# VPAC0_COMMON_0_IVPAC_TOP_0_CFG_SLV_PAR_VPAC_VISS0_S_VBUSP_VISS_RAWFE_CFG_MMR_S_VBUSP_RAWFE_CFG register map
Vendor: Texas Instruments
Peripheral module from a debugger description file (folder am62A).
Registers are 32-bit, read-write, reset 0x0 unless marked. A register's access mark holds for its fields unless they carry their own. Offsets are as the file gives them; lines under a group give offsets from that group; [hi:lo] are bit positions; {n}, {i} and the like mark numbered series; 'fields as' and 'values as' point back to an identical list; <NAME> marks a mode.

## VPAC0_COMMON_0_IVPAC_TOP_0_CFG_SLV_PAR_VPAC_VISS0_S_VBUSP_VISS_RAWFE_CFG_MMR_S_VBUSP_RAWFE_CFG
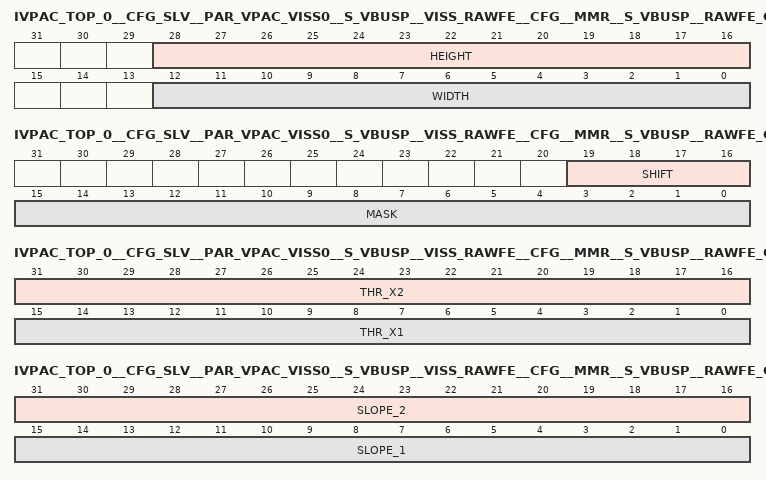
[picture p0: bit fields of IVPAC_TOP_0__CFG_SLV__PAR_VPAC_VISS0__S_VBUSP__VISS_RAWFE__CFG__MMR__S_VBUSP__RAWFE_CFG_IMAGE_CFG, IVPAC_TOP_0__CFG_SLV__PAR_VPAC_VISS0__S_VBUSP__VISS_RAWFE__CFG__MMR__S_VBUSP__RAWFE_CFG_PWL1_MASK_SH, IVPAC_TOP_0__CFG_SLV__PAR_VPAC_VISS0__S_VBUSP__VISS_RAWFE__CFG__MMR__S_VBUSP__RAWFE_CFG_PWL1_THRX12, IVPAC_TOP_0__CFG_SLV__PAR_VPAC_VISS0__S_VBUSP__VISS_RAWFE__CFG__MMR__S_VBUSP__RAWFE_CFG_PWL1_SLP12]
0x00 IVPAC_TOP_0__CFG_SLV__PAR_VPAC_VISS0__S_VBUSP__VISS_RAWFE__CFG__MMR__S_VBUSP__RAWFE_CFG_IMAGE_CFG — Input image width and height.
  [28:16] HEIGHT — image height
  [12:0] WIDTH — image width
0x04 IVPAC_TOP_0__CFG_SLV__PAR_VPAC_VISS0__S_VBUSP__VISS_RAWFE__CFG__MMR__S_VBUSP__RAWFE_CFG_SHADOW_CFG — shadow configuration
  [0] LUT3_SHDW_EN — use LUT2 ram as LUT table for LUT3 processing
0x08 IVPAC_TOP_0__CFG_SLV__PAR_VPAC_VISS0__S_VBUSP__VISS_RAWFE__CFG__MMR__S_VBUSP__RAWFE_CFG_PWL1_MASK_SH — Long frame PWL mask and shift values
  [19:16] SHIFT — number of right shift
  [15:0] MASK — mask bit pattern
0x0C IVPAC_TOP_0__CFG_SLV__PAR_VPAC_VISS0__S_VBUSP__VISS_RAWFE__CFG__MMR__S_VBUSP__RAWFE_CFG_PWL1_EN — Long frame PWL enable
  [0] ENABLE
0x10 IVPAC_TOP_0__CFG_SLV__PAR_VPAC_VISS0__S_VBUSP__VISS_RAWFE__CFG__MMR__S_VBUSP__RAWFE_CFG_PWL1_THRX12 — Long frame PWL threshold X1 and X2 - Unsigned
  [31:16] THR_X2 — threshold X2
  [15:0] THR_X1 — threshold X1
0x14 IVPAC_TOP_0__CFG_SLV__PAR_VPAC_VISS0__S_VBUSP__VISS_RAWFE__CFG__MMR__S_VBUSP__RAWFE_CFG_PWL1_THRX3 — Long frame PWL threshold X3 - Unsigned
  [15:0] THR_X3 — threshold X3
{0x14+4i} IVPAC_TOP_0__CFG_SLV__PAR_VPAC_VISS0__S_VBUSP__VISS_RAWFE__CFG__MMR__S_VBUSP__RAWFE_CFG_PWL1_THRY{i} (i=1..3) — Long frame PWL threshold Y{i} - Unsigned
  [23:0] THR_Y{i} — threshold Y{i}
0x24 IVPAC_TOP_0__CFG_SLV__PAR_VPAC_VISS0__S_VBUSP__VISS_RAWFE__CFG__MMR__S_VBUSP__RAWFE_CFG_PWL1_SLP12 — Long frame PWL slope 1 and 2 - Unsigned
  [31:16] SLOPE_2, [15:0] SLOPE_1
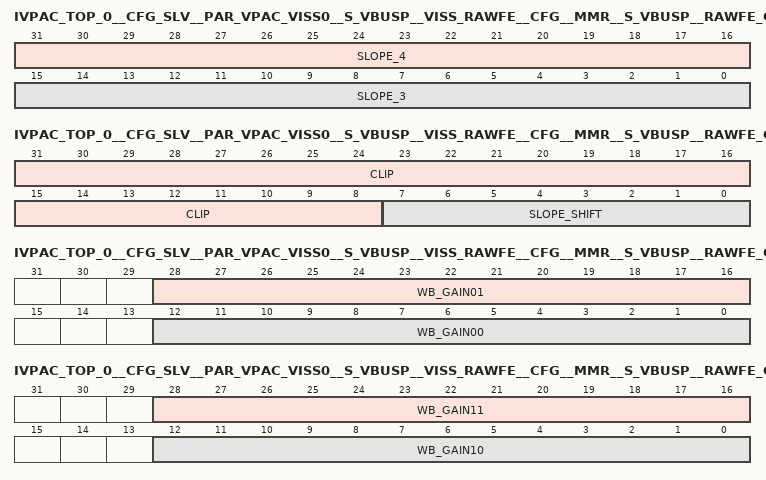
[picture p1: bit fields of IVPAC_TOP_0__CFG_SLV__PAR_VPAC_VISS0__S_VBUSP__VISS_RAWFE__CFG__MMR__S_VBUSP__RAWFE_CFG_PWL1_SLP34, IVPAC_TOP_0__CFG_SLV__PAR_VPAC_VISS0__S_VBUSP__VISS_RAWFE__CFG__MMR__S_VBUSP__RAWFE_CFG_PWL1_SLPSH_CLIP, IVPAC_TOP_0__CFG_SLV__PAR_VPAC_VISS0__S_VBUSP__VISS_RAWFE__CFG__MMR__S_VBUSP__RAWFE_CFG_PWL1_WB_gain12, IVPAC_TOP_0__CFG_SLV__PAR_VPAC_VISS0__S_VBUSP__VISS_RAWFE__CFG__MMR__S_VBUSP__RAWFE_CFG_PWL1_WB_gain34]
0x28 IVPAC_TOP_0__CFG_SLV__PAR_VPAC_VISS0__S_VBUSP__VISS_RAWFE__CFG__MMR__S_VBUSP__RAWFE_CFG_PWL1_SLP34 — Long frame PWL slope 3 and 4 - Unsigned
  [31:16] SLOPE_4, [15:0] SLOPE_3
0x2C IVPAC_TOP_0__CFG_SLV__PAR_VPAC_VISS0__S_VBUSP__VISS_RAWFE__CFG__MMR__S_VBUSP__RAWFE_CFG_PWL1_SLPSH_CLIP — Long frame PWL slope shift and clip
  [31:8] CLIP — clip value
  [7:0] SLOPE_SHIFT — shift value for slope, must not exceed decimal 31.
0x30 IVPAC_TOP_0__CFG_SLV__PAR_VPAC_VISS0__S_VBUSP__VISS_RAWFE__CFG__MMR__S_VBUSP__RAWFE_CFG_PWL1_OFF1 access not given — Long frame Offset 1
  [23:0] OFST00 rw — S24, Offset at pixel 00
0x34 IVPAC_TOP_0__CFG_SLV__PAR_VPAC_VISS0__S_VBUSP__VISS_RAWFE__CFG__MMR__S_VBUSP__RAWFE_CFG_PWL1_OFF2 access not given — Long frame Offset 2
  [23:0] OFST01 rw — S24, Offset at pixel 01
0x38 IVPAC_TOP_0__CFG_SLV__PAR_VPAC_VISS0__S_VBUSP__VISS_RAWFE__CFG__MMR__S_VBUSP__RAWFE_CFG_PWL1_OFF3 access not given — Long frame Offset 3
  [23:0] OFST10 rw — S24, Offset at pixel 10
0x3C IVPAC_TOP_0__CFG_SLV__PAR_VPAC_VISS0__S_VBUSP__VISS_RAWFE__CFG__MMR__S_VBUSP__RAWFE_CFG_PWL1_OFF4 access not given — Long frame Offset 4
  [23:0] OFST11 rw — S24, Offset at pixel 11
0x40 IVPAC_TOP_0__CFG_SLV__PAR_VPAC_VISS0__S_VBUSP__VISS_RAWFE__CFG__MMR__S_VBUSP__RAWFE_CFG_PWL1_WB_gain12 — Long Frame white balance gain 1 and 2
  [28:16] WB_GAIN01 — U13Q9, WB gain at pixel 01
  [12:0] WB_GAIN00 — U13Q9, WB gain at pixel 00
0x44 IVPAC_TOP_0__CFG_SLV__PAR_VPAC_VISS0__S_VBUSP__VISS_RAWFE__CFG__MMR__S_VBUSP__RAWFE_CFG_PWL1_WB_gain34 — Long Frame white balance gain 3 and 4
  [28:16] WB_GAIN11 — U13Q9, WB gain at pixel 11
  [12:0] WB_GAIN10 — U13Q9, WB gain at pixel 10
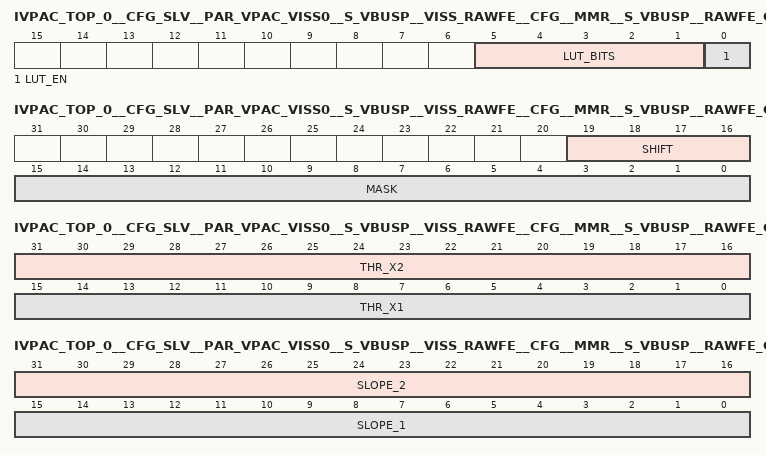
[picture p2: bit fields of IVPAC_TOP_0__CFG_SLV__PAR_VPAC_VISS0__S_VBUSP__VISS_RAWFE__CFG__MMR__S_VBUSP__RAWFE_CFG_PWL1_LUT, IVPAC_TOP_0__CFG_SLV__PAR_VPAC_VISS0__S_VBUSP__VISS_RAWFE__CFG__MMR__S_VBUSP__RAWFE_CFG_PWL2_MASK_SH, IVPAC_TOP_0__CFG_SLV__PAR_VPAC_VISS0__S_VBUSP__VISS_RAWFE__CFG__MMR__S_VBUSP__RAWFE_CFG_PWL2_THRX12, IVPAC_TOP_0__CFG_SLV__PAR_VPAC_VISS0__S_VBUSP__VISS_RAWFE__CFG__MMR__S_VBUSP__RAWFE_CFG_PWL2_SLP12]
0x48 IVPAC_TOP_0__CFG_SLV__PAR_VPAC_VISS0__S_VBUSP__VISS_RAWFE__CFG__MMR__S_VBUSP__RAWFE_CFG_PWL1_LUT — Long frame PWL LUT configuration
  [5:1] LUT_BITS — LUT input bit depth, up to 24
  [0] LUT_EN — enable LUT based compression
0x4C IVPAC_TOP_0__CFG_SLV__PAR_VPAC_VISS0__S_VBUSP__VISS_RAWFE__CFG__MMR__S_VBUSP__RAWFE_CFG_PWL1_LUTCLIP — Long frame PWL LUT output clip value
  [15:0] LUTCLIP — LUT clip value
0x50 IVPAC_TOP_0__CFG_SLV__PAR_VPAC_VISS0__S_VBUSP__VISS_RAWFE__CFG__MMR__S_VBUSP__RAWFE_CFG_PWL2_MASK_SH — Short frame PWL mask and shift values
  fields as IVPAC_TOP_0__CFG_SLV__PAR_VPAC_VISS0__S_VBUSP__VISS_RAWFE__CFG__MMR__S_VBUSP__RAWFE_CFG_PWL1_MASK_SH
0x54 IVPAC_TOP_0__CFG_SLV__PAR_VPAC_VISS0__S_VBUSP__VISS_RAWFE__CFG__MMR__S_VBUSP__RAWFE_CFG_PWL2_EN — Short frame PWL enable
  [0] ENABLE
0x58 IVPAC_TOP_0__CFG_SLV__PAR_VPAC_VISS0__S_VBUSP__VISS_RAWFE__CFG__MMR__S_VBUSP__RAWFE_CFG_PWL2_THRX12 — Short frame PWL threshold X1 and X2 - Unsigned
  [31:16] THR_X2 — threshold X2
  [15:0] THR_X1 — threshold X1
0x5C IVPAC_TOP_0__CFG_SLV__PAR_VPAC_VISS0__S_VBUSP__VISS_RAWFE__CFG__MMR__S_VBUSP__RAWFE_CFG_PWL2_THRX3 — Short frame PWL threshold X3 - Unsigned
  [15:0] THR_X3 — threshold X3
{0x5C+4i} IVPAC_TOP_0__CFG_SLV__PAR_VPAC_VISS0__S_VBUSP__VISS_RAWFE__CFG__MMR__S_VBUSP__RAWFE_CFG_PWL2_THRY{i} (i=1..3) — Short frame PWL threshold Y{i} - Unsigned
  [23:0] THR_Y{i} — threshold Y{i}
0x6C IVPAC_TOP_0__CFG_SLV__PAR_VPAC_VISS0__S_VBUSP__VISS_RAWFE__CFG__MMR__S_VBUSP__RAWFE_CFG_PWL2_SLP12 — Short frame PWL slope 1 and 2 - Unsigned
  [31:16] SLOPE_2, [15:0] SLOPE_1
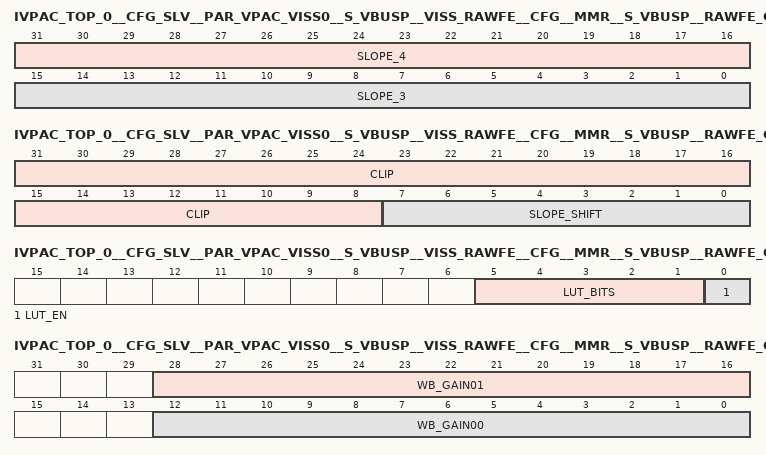
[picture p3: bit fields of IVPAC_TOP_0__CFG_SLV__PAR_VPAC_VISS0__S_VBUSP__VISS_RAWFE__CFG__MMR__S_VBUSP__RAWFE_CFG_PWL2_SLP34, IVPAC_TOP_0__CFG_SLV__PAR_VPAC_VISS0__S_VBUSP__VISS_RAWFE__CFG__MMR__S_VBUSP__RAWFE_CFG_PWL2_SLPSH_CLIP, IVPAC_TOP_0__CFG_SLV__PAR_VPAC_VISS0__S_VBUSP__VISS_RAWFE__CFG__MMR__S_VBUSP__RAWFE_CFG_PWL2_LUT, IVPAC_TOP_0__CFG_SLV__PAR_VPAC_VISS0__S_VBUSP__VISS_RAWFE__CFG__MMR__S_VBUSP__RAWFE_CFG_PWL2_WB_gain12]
0x70 IVPAC_TOP_0__CFG_SLV__PAR_VPAC_VISS0__S_VBUSP__VISS_RAWFE__CFG__MMR__S_VBUSP__RAWFE_CFG_PWL2_SLP34 — Short frame PWL slope 3 and 4 - Unsigned
  [31:16] SLOPE_4, [15:0] SLOPE_3
0x74 IVPAC_TOP_0__CFG_SLV__PAR_VPAC_VISS0__S_VBUSP__VISS_RAWFE__CFG__MMR__S_VBUSP__RAWFE_CFG_PWL2_SLPSH_CLIP — Short frame PWL slope shift and clip
  [31:8] CLIP — clip value
  [7:0] SLOPE_SHIFT — shift value for slope, must not exceed decimal 31
0x78 IVPAC_TOP_0__CFG_SLV__PAR_VPAC_VISS0__S_VBUSP__VISS_RAWFE__CFG__MMR__S_VBUSP__RAWFE_CFG_PWL2_LUT — Short frame PWL LUT configuration
  fields as IVPAC_TOP_0__CFG_SLV__PAR_VPAC_VISS0__S_VBUSP__VISS_RAWFE__CFG__MMR__S_VBUSP__RAWFE_CFG_PWL1_LUT
0x7C IVPAC_TOP_0__CFG_SLV__PAR_VPAC_VISS0__S_VBUSP__VISS_RAWFE__CFG__MMR__S_VBUSP__RAWFE_CFG_PWL2_LUTCLIP — Short frame PWL LUT output clip value
  [15:0] LUTCLIP — LUT clip value
0x80 IVPAC_TOP_0__CFG_SLV__PAR_VPAC_VISS0__S_VBUSP__VISS_RAWFE__CFG__MMR__S_VBUSP__RAWFE_CFG_PWL2_OFF1 access not given — Short frame WB Offset 1
  [23:0] OFST00 rw — S24, WB Offset at pixel 00
0x84 IVPAC_TOP_0__CFG_SLV__PAR_VPAC_VISS0__S_VBUSP__VISS_RAWFE__CFG__MMR__S_VBUSP__RAWFE_CFG_PWL2_OFF2 access not given — Short frame Offset 2
  [23:0] OFST01 rw — S24, Offset at pixel 01
0x88 IVPAC_TOP_0__CFG_SLV__PAR_VPAC_VISS0__S_VBUSP__VISS_RAWFE__CFG__MMR__S_VBUSP__RAWFE_CFG_PWL2_OFF3 access not given — Short frame Offset 3
  [23:0] OFST10 rw — S24, Offset at pixel 10
0x8C IVPAC_TOP_0__CFG_SLV__PAR_VPAC_VISS0__S_VBUSP__VISS_RAWFE__CFG__MMR__S_VBUSP__RAWFE_CFG_PWL2_OFF4 access not given — Short frame Offset 4
  [23:0] OFST11 rw — S24, Offset at pixel 11
0x90 IVPAC_TOP_0__CFG_SLV__PAR_VPAC_VISS0__S_VBUSP__VISS_RAWFE__CFG__MMR__S_VBUSP__RAWFE_CFG_PWL2_WB_gain12 — Short Frame white balance gain 1 and 2
  fields as IVPAC_TOP_0__CFG_SLV__PAR_VPAC_VISS0__S_VBUSP__VISS_RAWFE__CFG__MMR__S_VBUSP__RAWFE_CFG_PWL1_WB_gain12
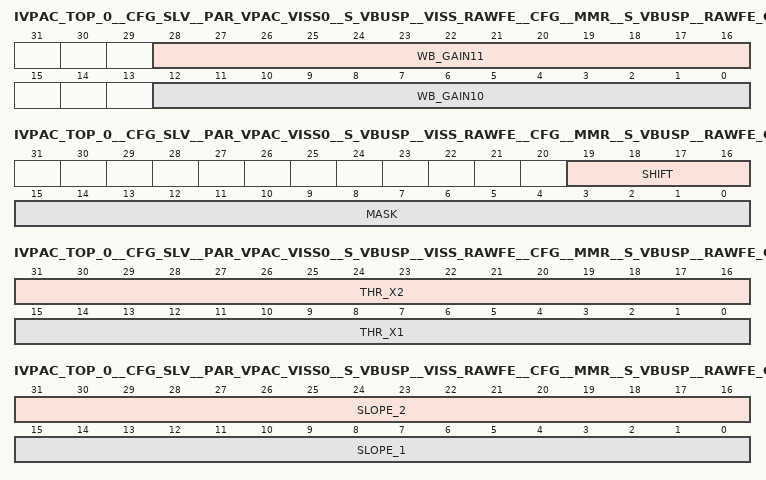
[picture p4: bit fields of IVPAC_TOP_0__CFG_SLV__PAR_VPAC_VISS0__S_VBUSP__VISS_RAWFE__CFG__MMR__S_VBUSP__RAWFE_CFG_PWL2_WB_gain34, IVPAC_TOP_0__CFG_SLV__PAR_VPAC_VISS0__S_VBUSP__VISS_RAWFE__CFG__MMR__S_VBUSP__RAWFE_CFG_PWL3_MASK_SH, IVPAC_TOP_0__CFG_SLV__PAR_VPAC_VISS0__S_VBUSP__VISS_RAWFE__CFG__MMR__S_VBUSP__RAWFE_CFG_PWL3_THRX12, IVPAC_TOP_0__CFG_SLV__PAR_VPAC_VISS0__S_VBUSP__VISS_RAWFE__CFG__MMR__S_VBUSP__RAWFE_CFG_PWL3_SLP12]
0x94 IVPAC_TOP_0__CFG_SLV__PAR_VPAC_VISS0__S_VBUSP__VISS_RAWFE__CFG__MMR__S_VBUSP__RAWFE_CFG_PWL2_WB_gain34 — Short Frame white balance gain 3 and 4
  fields as IVPAC_TOP_0__CFG_SLV__PAR_VPAC_VISS0__S_VBUSP__VISS_RAWFE__CFG__MMR__S_VBUSP__RAWFE_CFG_PWL1_WB_gain34
0x98 IVPAC_TOP_0__CFG_SLV__PAR_VPAC_VISS0__S_VBUSP__VISS_RAWFE__CFG__MMR__S_VBUSP__RAWFE_CFG_PWL3_MASK_SH — Very short frame PWL mask and shift values
  fields as IVPAC_TOP_0__CFG_SLV__PAR_VPAC_VISS0__S_VBUSP__VISS_RAWFE__CFG__MMR__S_VBUSP__RAWFE_CFG_PWL1_MASK_SH
0x9C IVPAC_TOP_0__CFG_SLV__PAR_VPAC_VISS0__S_VBUSP__VISS_RAWFE__CFG__MMR__S_VBUSP__RAWFE_CFG_PWL3_EN — Very short frame PWL enable
  [0] ENABLE
0xA0 IVPAC_TOP_0__CFG_SLV__PAR_VPAC_VISS0__S_VBUSP__VISS_RAWFE__CFG__MMR__S_VBUSP__RAWFE_CFG_PWL3_THRX12 — Very short frame PWL threshold X1 and X2 - Unsigned
  [31:16] THR_X2 — threshold X2
  [15:0] THR_X1 — threshold X1
0xA4 IVPAC_TOP_0__CFG_SLV__PAR_VPAC_VISS0__S_VBUSP__VISS_RAWFE__CFG__MMR__S_VBUSP__RAWFE_CFG_PWL3_THRX3 — Very short frame PWL threshold X3 - Unsigned
  [15:0] THR_X3 — threshold X3
{0xA4+4i} IVPAC_TOP_0__CFG_SLV__PAR_VPAC_VISS0__S_VBUSP__VISS_RAWFE__CFG__MMR__S_VBUSP__RAWFE_CFG_PWL3_THRY{i} (i=1..3) — Very short frame PWL threshold Y{i} - Unsigned
  [23:0] THR_Y{i} — threshold Y{i}
0xB4 IVPAC_TOP_0__CFG_SLV__PAR_VPAC_VISS0__S_VBUSP__VISS_RAWFE__CFG__MMR__S_VBUSP__RAWFE_CFG_PWL3_SLP12 — Very short frame PWL slope 1 and 2 - Unsigned
  [31:16] SLOPE_2, [15:0] SLOPE_1
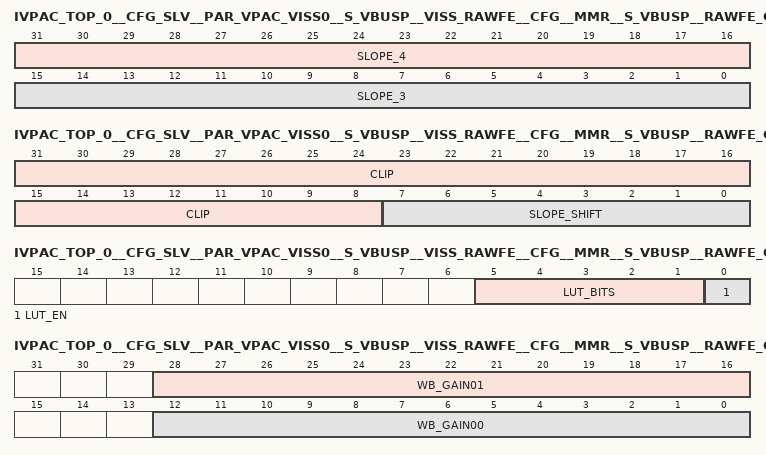
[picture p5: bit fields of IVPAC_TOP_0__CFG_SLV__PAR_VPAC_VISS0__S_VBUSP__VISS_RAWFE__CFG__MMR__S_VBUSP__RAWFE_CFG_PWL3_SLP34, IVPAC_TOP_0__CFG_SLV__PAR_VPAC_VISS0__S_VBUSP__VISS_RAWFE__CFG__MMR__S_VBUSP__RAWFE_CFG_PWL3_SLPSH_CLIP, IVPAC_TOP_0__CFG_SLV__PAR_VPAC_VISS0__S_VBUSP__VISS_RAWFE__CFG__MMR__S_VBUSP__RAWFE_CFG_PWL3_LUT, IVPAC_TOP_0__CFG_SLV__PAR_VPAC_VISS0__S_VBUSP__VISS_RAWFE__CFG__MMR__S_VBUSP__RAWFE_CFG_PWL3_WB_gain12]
0xB8 IVPAC_TOP_0__CFG_SLV__PAR_VPAC_VISS0__S_VBUSP__VISS_RAWFE__CFG__MMR__S_VBUSP__RAWFE_CFG_PWL3_SLP34 — Very short frame PWL slope 3 and 4 - Unsigned
  [31:16] SLOPE_4, [15:0] SLOPE_3
0xBC IVPAC_TOP_0__CFG_SLV__PAR_VPAC_VISS0__S_VBUSP__VISS_RAWFE__CFG__MMR__S_VBUSP__RAWFE_CFG_PWL3_SLPSH_CLIP — Very short frame PWL slope shift and clip
  fields as IVPAC_TOP_0__CFG_SLV__PAR_VPAC_VISS0__S_VBUSP__VISS_RAWFE__CFG__MMR__S_VBUSP__RAWFE_CFG_PWL2_SLPSH_CLIP
0xC0 IVPAC_TOP_0__CFG_SLV__PAR_VPAC_VISS0__S_VBUSP__VISS_RAWFE__CFG__MMR__S_VBUSP__RAWFE_CFG_PWL3_LUT — Very short frame PWL LUT configuration
  fields as IVPAC_TOP_0__CFG_SLV__PAR_VPAC_VISS0__S_VBUSP__VISS_RAWFE__CFG__MMR__S_VBUSP__RAWFE_CFG_PWL1_LUT
0xC4 IVPAC_TOP_0__CFG_SLV__PAR_VPAC_VISS0__S_VBUSP__VISS_RAWFE__CFG__MMR__S_VBUSP__RAWFE_CFG_PWL3_LUTCLIP — Very short frame PWL LUT output clip value
  [15:0] LUTCLIP — LUT clip value
0xC8 IVPAC_TOP_0__CFG_SLV__PAR_VPAC_VISS0__S_VBUSP__VISS_RAWFE__CFG__MMR__S_VBUSP__RAWFE_CFG_PWL3_OFF1 access not given — Very Short frame Offset 1
  [23:0] OFST00 rw — S24, Offset at pixel 00
0xCC IVPAC_TOP_0__CFG_SLV__PAR_VPAC_VISS0__S_VBUSP__VISS_RAWFE__CFG__MMR__S_VBUSP__RAWFE_CFG_PWL3_OFF2 access not given — Very Short frame Offset 2
  [23:0] OFST01 rw — S24, Offset at pixel 01
0xD0 IVPAC_TOP_0__CFG_SLV__PAR_VPAC_VISS0__S_VBUSP__VISS_RAWFE__CFG__MMR__S_VBUSP__RAWFE_CFG_PWL3_OFF3 access not given — Very Short frame Offset 3
  [23:0] OFST10 rw — S24, Offset at pixel 10
0xD4 IVPAC_TOP_0__CFG_SLV__PAR_VPAC_VISS0__S_VBUSP__VISS_RAWFE__CFG__MMR__S_VBUSP__RAWFE_CFG_PWL3_OFF4 access not given — Very Short frame Offset 4
  [23:0] OFST11 rw — S24, Offset at pixel 11
0xD8 IVPAC_TOP_0__CFG_SLV__PAR_VPAC_VISS0__S_VBUSP__VISS_RAWFE__CFG__MMR__S_VBUSP__RAWFE_CFG_PWL3_WB_gain12 — Very Short Frame white balance gain 1 and 2
  fields as IVPAC_TOP_0__CFG_SLV__PAR_VPAC_VISS0__S_VBUSP__VISS_RAWFE__CFG__MMR__S_VBUSP__RAWFE_CFG_PWL1_WB_gain12
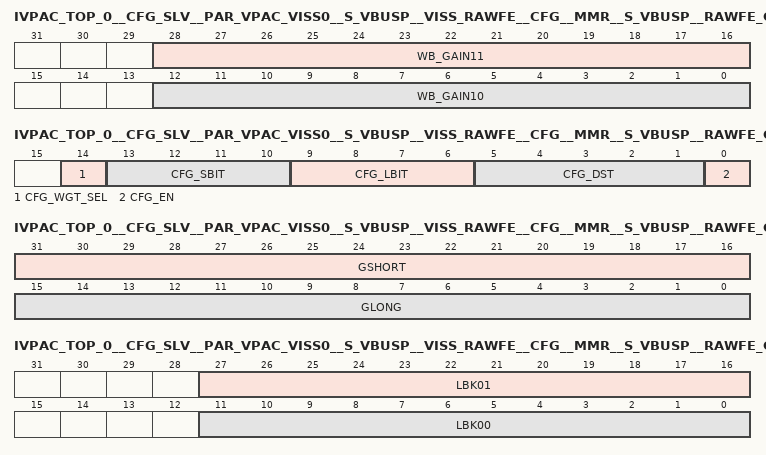
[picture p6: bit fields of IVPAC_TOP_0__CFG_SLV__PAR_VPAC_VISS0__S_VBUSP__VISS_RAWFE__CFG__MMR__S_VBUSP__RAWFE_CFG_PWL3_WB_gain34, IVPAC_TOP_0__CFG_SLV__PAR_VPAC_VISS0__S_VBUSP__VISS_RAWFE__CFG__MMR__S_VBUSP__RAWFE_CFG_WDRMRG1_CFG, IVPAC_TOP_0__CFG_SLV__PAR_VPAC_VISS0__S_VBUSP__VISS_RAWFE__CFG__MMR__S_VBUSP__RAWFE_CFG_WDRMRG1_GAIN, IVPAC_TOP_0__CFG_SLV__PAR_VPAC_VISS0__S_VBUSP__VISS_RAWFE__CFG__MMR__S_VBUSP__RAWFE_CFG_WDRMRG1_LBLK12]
0xDC IVPAC_TOP_0__CFG_SLV__PAR_VPAC_VISS0__S_VBUSP__VISS_RAWFE__CFG__MMR__S_VBUSP__RAWFE_CFG_PWL3_WB_gain34 — Very Short Frame white balance gain 3 and 4
  fields as IVPAC_TOP_0__CFG_SLV__PAR_VPAC_VISS0__S_VBUSP__VISS_RAWFE__CFG__MMR__S_VBUSP__RAWFE_CFG_PWL1_WB_gain34
0xE0 IVPAC_TOP_0__CFG_SLV__PAR_VPAC_VISS0__S_VBUSP__VISS_RAWFE__CFG__MMR__S_VBUSP__RAWFE_CFG_WDRMRG1_CFG — First stage WDR merge configuration
  [14] CFG_WGT_SEL — Select source for weight calculation (0:long, 1: short)
  [13:10] CFG_SBIT — U4, short exposure image bit shift
  [9:6] CFG_LBIT — U4, long exposure image bit shift
  [5:1] CFG_DST — U5, down shift value after WDR merge
  [0] CFG_EN — enable
0xE4 IVPAC_TOP_0__CFG_SLV__PAR_VPAC_VISS0__S_VBUSP__VISS_RAWFE__CFG__MMR__S_VBUSP__RAWFE_CFG_WDRMRG1_GAIN — First stage WDR merge gain
  [31:16] GSHORT — U16Q15, gain for long frame
  [15:0] GLONG — U16Q15, gain for short frame
0xE8 IVPAC_TOP_0__CFG_SLV__PAR_VPAC_VISS0__S_VBUSP__VISS_RAWFE__CFG__MMR__S_VBUSP__RAWFE_CFG_WDRMRG1_LBLK12 — First stage WDR merge black level 1 and 2 for long frame
  [27:16] LBK01 — U12, black level for long frame at pixel 01
  [11:0] LBK00 — U12, black level for long frame at pixel 00
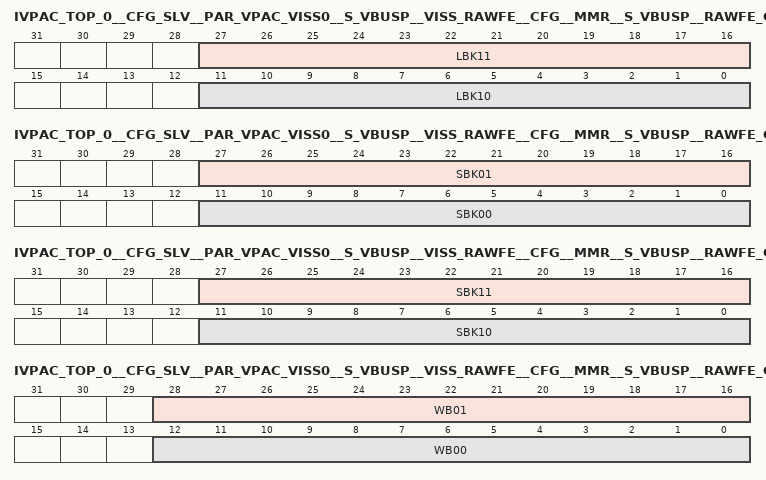
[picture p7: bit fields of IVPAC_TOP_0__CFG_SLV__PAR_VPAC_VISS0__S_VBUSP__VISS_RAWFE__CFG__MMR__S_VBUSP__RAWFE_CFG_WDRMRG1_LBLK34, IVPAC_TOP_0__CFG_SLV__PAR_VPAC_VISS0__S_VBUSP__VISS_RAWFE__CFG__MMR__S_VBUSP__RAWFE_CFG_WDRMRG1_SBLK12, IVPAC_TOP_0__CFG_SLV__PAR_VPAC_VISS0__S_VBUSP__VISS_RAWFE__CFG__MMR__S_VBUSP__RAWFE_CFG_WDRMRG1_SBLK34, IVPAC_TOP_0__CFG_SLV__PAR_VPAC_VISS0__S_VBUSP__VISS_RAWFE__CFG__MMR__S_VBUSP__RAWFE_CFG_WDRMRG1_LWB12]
0xEC IVPAC_TOP_0__CFG_SLV__PAR_VPAC_VISS0__S_VBUSP__VISS_RAWFE__CFG__MMR__S_VBUSP__RAWFE_CFG_WDRMRG1_LBLK34 — First stage WDR merge black level 3 and 4 for long frame
  [27:16] LBK11 — U12, black level for long frame at pixel 11
  [11:0] LBK10 — U12, black level for long frame at pixel 10
0xF0 IVPAC_TOP_0__CFG_SLV__PAR_VPAC_VISS0__S_VBUSP__VISS_RAWFE__CFG__MMR__S_VBUSP__RAWFE_CFG_WDRMRG1_SBLK12 — First stage WDR merge black level 1 and 2 for short frame
  [27:16] SBK01 — U12, black level for short frame at pixel 01
  [11:0] SBK00 — U12, black level for short frame at pixel 00
0xF4 IVPAC_TOP_0__CFG_SLV__PAR_VPAC_VISS0__S_VBUSP__VISS_RAWFE__CFG__MMR__S_VBUSP__RAWFE_CFG_WDRMRG1_SBLK34 — First stage WDR merge black level 3 and 4 for short frame
  [27:16] SBK11 — U12, black level for short frame at pixel 11
  [11:0] SBK10 — U12, black level for short frame at pixel 10
0xF8 IVPAC_TOP_0__CFG_SLV__PAR_VPAC_VISS0__S_VBUSP__VISS_RAWFE__CFG__MMR__S_VBUSP__RAWFE_CFG_WDRMRG1_LWB12 — First stage WDR merge WB gain 1 and 2 for long frame
  [28:16] WB01 — U13Q9, WB gain for long frame at pixel 01
  [12:0] WB00 — U13Q9, WB gain for long frame at pixel 00
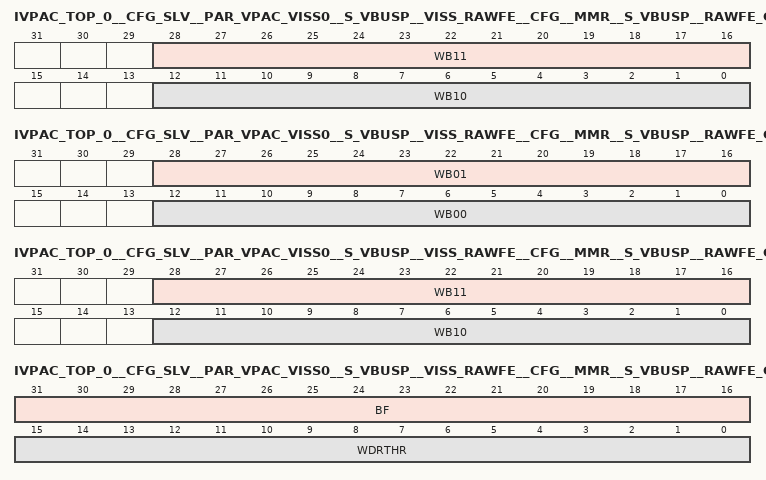
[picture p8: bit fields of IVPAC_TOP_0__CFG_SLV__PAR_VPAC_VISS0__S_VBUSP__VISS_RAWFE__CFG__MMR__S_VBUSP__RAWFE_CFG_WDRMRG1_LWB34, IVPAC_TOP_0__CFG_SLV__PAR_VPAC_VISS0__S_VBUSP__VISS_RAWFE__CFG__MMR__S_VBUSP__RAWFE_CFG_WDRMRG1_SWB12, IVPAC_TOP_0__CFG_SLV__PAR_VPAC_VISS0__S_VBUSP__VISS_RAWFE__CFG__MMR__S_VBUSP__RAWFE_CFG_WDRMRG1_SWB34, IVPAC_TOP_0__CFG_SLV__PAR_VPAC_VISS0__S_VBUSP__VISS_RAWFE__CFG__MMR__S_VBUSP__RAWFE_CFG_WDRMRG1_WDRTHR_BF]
0xFC IVPAC_TOP_0__CFG_SLV__PAR_VPAC_VISS0__S_VBUSP__VISS_RAWFE__CFG__MMR__S_VBUSP__RAWFE_CFG_WDRMRG1_LWB34 — First stage WDR merge WB gain 3 and 4 for long frame
  [28:16] WB11 — U13Q9, WB gain for long frame at pixel 11
  [12:0] WB10 — U13Q9, WB gain for long frame at pixel 10
0x100 IVPAC_TOP_0__CFG_SLV__PAR_VPAC_VISS0__S_VBUSP__VISS_RAWFE__CFG__MMR__S_VBUSP__RAWFE_CFG_WDRMRG1_SWB12 — First stage WDR merge WB gain 1 and 2 for short frame
  [28:16] WB01 — U13Q9, WB gain for short frame at pixel 01
  [12:0] WB00 — U13Q9, WB gain for short frame at pixel 00
0x104 IVPAC_TOP_0__CFG_SLV__PAR_VPAC_VISS0__S_VBUSP__VISS_RAWFE__CFG__MMR__S_VBUSP__RAWFE_CFG_WDRMRG1_SWB34 — First stage WDR merge WB gain 3 and 4 for short frame
  [28:16] WB11 — U13Q9, WB gain for short frame at pixel 11
  [12:0] WB10 — U13Q9, WB gain for short frame at pixel 10
0x108 IVPAC_TOP_0__CFG_SLV__PAR_VPAC_VISS0__S_VBUSP__VISS_RAWFE__CFG__MMR__S_VBUSP__RAWFE_CFG_WDRMRG1_WDRTHR_BF — First stage WDR merge parameter WDRTHR and BF
  [31:16] BF — S16, bf parameter for merge
  [15:0] WDRTHR — U16, WDR threshold for merge
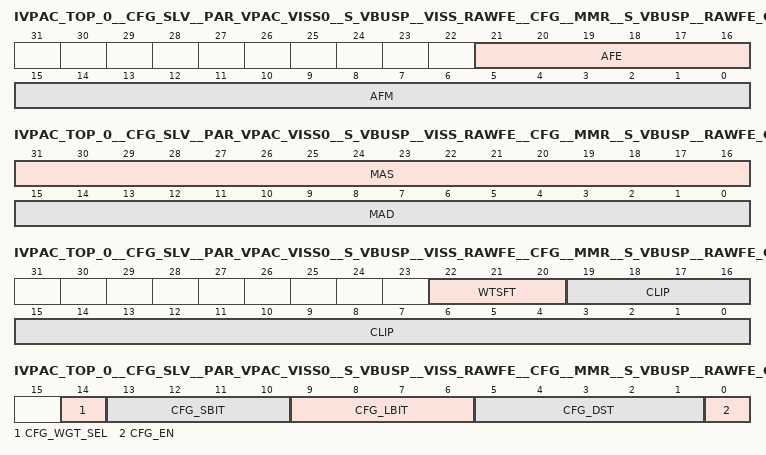
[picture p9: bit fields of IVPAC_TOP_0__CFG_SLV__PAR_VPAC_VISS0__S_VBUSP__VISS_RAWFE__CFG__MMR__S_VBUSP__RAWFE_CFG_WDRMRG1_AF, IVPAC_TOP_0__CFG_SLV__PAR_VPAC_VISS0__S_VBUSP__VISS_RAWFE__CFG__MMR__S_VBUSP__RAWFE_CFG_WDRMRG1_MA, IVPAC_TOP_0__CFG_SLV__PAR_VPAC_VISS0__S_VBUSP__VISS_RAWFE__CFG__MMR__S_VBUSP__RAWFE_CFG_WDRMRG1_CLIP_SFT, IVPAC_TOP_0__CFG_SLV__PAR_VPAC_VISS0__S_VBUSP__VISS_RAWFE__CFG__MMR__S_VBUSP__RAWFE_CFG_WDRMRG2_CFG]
0x10C IVPAC_TOP_0__CFG_SLV__PAR_VPAC_VISS0__S_VBUSP__VISS_RAWFE__CFG__MMR__S_VBUSP__RAWFE_CFG_WDRMRG1_AF — First stage WDR merge parameter AF
  [21:16] AFE — U6, af_e parameter for merge
  [15:0] AFM — S16, af_m parameter for merge
0x110 IVPAC_TOP_0__CFG_SLV__PAR_VPAC_VISS0__S_VBUSP__VISS_RAWFE__CFG__MMR__S_VBUSP__RAWFE_CFG_WDRMRG1_MA — First stage WDR merge parameter MA
  [31:16] MAS — U16, slope for merge MA filter
  [15:0] MAD — U16, lower threshold for merge MA filter
0x114 IVPAC_TOP_0__CFG_SLV__PAR_VPAC_VISS0__S_VBUSP__VISS_RAWFE__CFG__MMR__S_VBUSP__RAWFE_CFG_WDRMRG1_CLIP_SFT — First stage WDR merge clip value and shift before weight block
  [22:20] WTSFT — U3, shift before weight block
  [19:0] CLIP — U20, output clip value. It is a software restriction to always ensure that the clipped value is a 16-bit number for first wdr stage.
0x118 IVPAC_TOP_0__CFG_SLV__PAR_VPAC_VISS0__S_VBUSP__VISS_RAWFE__CFG__MMR__S_VBUSP__RAWFE_CFG_WDRMRG2_CFG — Second stage WDR merge configuration
  fields as IVPAC_TOP_0__CFG_SLV__PAR_VPAC_VISS0__S_VBUSP__VISS_RAWFE__CFG__MMR__S_VBUSP__RAWFE_CFG_WDRMRG1_CFG
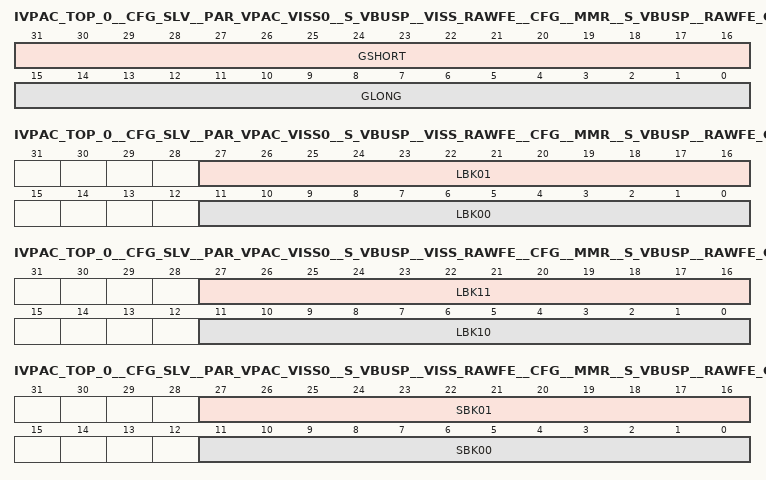
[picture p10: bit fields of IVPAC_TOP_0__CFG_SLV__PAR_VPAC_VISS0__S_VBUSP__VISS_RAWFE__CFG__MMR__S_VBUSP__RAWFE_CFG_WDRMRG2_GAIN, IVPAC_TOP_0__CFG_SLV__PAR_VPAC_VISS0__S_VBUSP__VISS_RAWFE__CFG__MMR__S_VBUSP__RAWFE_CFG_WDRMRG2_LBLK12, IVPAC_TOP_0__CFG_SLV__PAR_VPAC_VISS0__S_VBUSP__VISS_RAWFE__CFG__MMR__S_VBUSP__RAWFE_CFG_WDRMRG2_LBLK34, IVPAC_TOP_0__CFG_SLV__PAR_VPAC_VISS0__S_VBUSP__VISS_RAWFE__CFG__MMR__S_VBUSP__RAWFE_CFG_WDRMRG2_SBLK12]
0x11C IVPAC_TOP_0__CFG_SLV__PAR_VPAC_VISS0__S_VBUSP__VISS_RAWFE__CFG__MMR__S_VBUSP__RAWFE_CFG_WDRMRG2_GAIN — Second stage WDR merge gain
  fields as IVPAC_TOP_0__CFG_SLV__PAR_VPAC_VISS0__S_VBUSP__VISS_RAWFE__CFG__MMR__S_VBUSP__RAWFE_CFG_WDRMRG1_GAIN
0x120 IVPAC_TOP_0__CFG_SLV__PAR_VPAC_VISS0__S_VBUSP__VISS_RAWFE__CFG__MMR__S_VBUSP__RAWFE_CFG_WDRMRG2_LBLK12 — Second stage WDR merge black level 1 and 2 for long frame
  fields as IVPAC_TOP_0__CFG_SLV__PAR_VPAC_VISS0__S_VBUSP__VISS_RAWFE__CFG__MMR__S_VBUSP__RAWFE_CFG_WDRMRG1_LBLK12
0x124 IVPAC_TOP_0__CFG_SLV__PAR_VPAC_VISS0__S_VBUSP__VISS_RAWFE__CFG__MMR__S_VBUSP__RAWFE_CFG_WDRMRG2_LBLK34 — Second stage WDR merge black level 3 and 4 for long frame
  fields as IVPAC_TOP_0__CFG_SLV__PAR_VPAC_VISS0__S_VBUSP__VISS_RAWFE__CFG__MMR__S_VBUSP__RAWFE_CFG_WDRMRG1_LBLK34
0x128 IVPAC_TOP_0__CFG_SLV__PAR_VPAC_VISS0__S_VBUSP__VISS_RAWFE__CFG__MMR__S_VBUSP__RAWFE_CFG_WDRMRG2_SBLK12 — Second stage WDR merge black level 1 and 2 for short frame
  fields as IVPAC_TOP_0__CFG_SLV__PAR_VPAC_VISS0__S_VBUSP__VISS_RAWFE__CFG__MMR__S_VBUSP__RAWFE_CFG_WDRMRG1_SBLK12
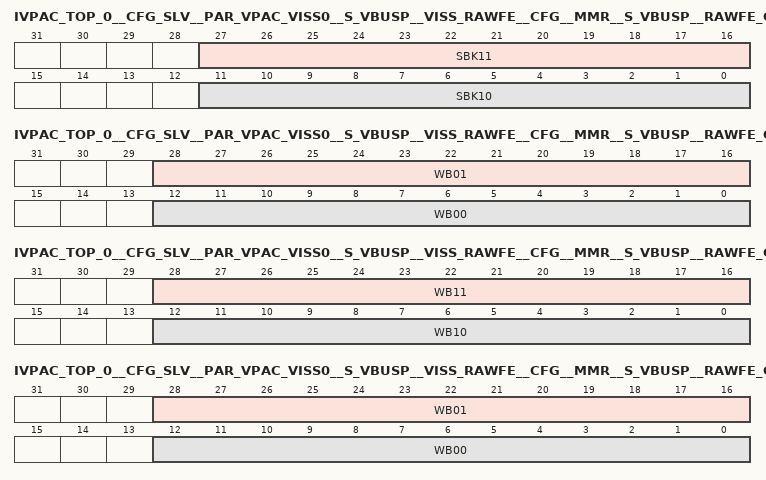
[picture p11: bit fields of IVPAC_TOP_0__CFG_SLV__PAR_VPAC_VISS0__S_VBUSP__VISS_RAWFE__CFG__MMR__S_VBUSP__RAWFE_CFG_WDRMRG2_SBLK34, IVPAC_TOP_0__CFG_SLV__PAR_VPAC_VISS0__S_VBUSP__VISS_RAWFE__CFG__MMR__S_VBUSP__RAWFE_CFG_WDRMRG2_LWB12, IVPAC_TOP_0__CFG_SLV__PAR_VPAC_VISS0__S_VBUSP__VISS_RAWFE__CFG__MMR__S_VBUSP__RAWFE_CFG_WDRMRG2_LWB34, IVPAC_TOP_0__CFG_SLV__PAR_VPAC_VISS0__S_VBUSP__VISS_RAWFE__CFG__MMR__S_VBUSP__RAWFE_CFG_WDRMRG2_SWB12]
0x12C IVPAC_TOP_0__CFG_SLV__PAR_VPAC_VISS0__S_VBUSP__VISS_RAWFE__CFG__MMR__S_VBUSP__RAWFE_CFG_WDRMRG2_SBLK34 — Second stage WDR merge black level 3 and 4 for short frame
  fields as IVPAC_TOP_0__CFG_SLV__PAR_VPAC_VISS0__S_VBUSP__VISS_RAWFE__CFG__MMR__S_VBUSP__RAWFE_CFG_WDRMRG1_SBLK34
0x130 IVPAC_TOP_0__CFG_SLV__PAR_VPAC_VISS0__S_VBUSP__VISS_RAWFE__CFG__MMR__S_VBUSP__RAWFE_CFG_WDRMRG2_LWB12 — Second stage WDR merge WB gain 1 and 2 for long frame
  fields as IVPAC_TOP_0__CFG_SLV__PAR_VPAC_VISS0__S_VBUSP__VISS_RAWFE__CFG__MMR__S_VBUSP__RAWFE_CFG_WDRMRG1_LWB12
0x134 IVPAC_TOP_0__CFG_SLV__PAR_VPAC_VISS0__S_VBUSP__VISS_RAWFE__CFG__MMR__S_VBUSP__RAWFE_CFG_WDRMRG2_LWB34 — Second stage WDR merge WB gain 3 and 4 for long frame
  fields as IVPAC_TOP_0__CFG_SLV__PAR_VPAC_VISS0__S_VBUSP__VISS_RAWFE__CFG__MMR__S_VBUSP__RAWFE_CFG_WDRMRG1_LWB34
0x138 IVPAC_TOP_0__CFG_SLV__PAR_VPAC_VISS0__S_VBUSP__VISS_RAWFE__CFG__MMR__S_VBUSP__RAWFE_CFG_WDRMRG2_SWB12 — Second stage WDR merge WB gain 1 and 2 for short frame
  fields as IVPAC_TOP_0__CFG_SLV__PAR_VPAC_VISS0__S_VBUSP__VISS_RAWFE__CFG__MMR__S_VBUSP__RAWFE_CFG_WDRMRG1_SWB12
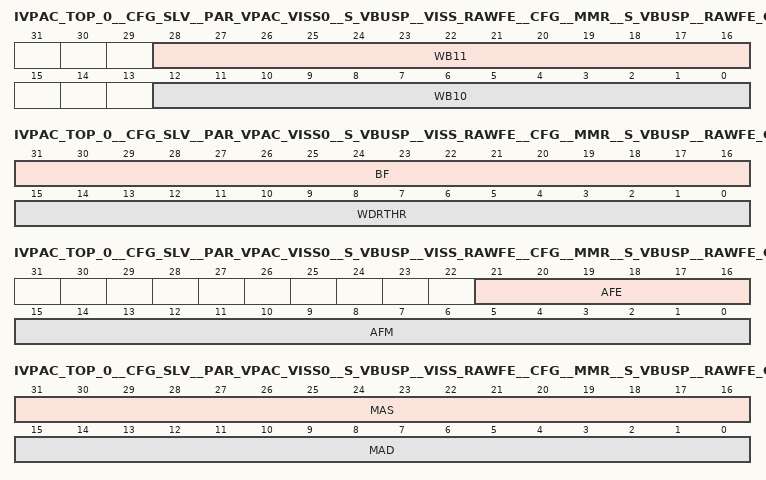
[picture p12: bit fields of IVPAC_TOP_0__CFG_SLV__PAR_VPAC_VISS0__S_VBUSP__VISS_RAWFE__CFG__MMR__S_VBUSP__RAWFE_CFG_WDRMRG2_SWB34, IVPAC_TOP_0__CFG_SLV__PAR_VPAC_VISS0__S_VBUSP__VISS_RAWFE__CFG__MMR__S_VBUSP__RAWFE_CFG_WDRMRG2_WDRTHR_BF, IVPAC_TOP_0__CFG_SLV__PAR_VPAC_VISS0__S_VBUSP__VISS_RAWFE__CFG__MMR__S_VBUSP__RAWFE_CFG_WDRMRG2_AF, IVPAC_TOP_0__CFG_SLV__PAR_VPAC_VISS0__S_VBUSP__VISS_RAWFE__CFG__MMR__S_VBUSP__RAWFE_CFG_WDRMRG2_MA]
0x13C IVPAC_TOP_0__CFG_SLV__PAR_VPAC_VISS0__S_VBUSP__VISS_RAWFE__CFG__MMR__S_VBUSP__RAWFE_CFG_WDRMRG2_SWB34 — Second stage WDR merge WB gain 3 and 4 for short frame
  fields as IVPAC_TOP_0__CFG_SLV__PAR_VPAC_VISS0__S_VBUSP__VISS_RAWFE__CFG__MMR__S_VBUSP__RAWFE_CFG_WDRMRG1_SWB34
0x140 IVPAC_TOP_0__CFG_SLV__PAR_VPAC_VISS0__S_VBUSP__VISS_RAWFE__CFG__MMR__S_VBUSP__RAWFE_CFG_WDRMRG2_WDRTHR_BF — Second stage WDR merge parameter WDRTHR and BF
  fields as IVPAC_TOP_0__CFG_SLV__PAR_VPAC_VISS0__S_VBUSP__VISS_RAWFE__CFG__MMR__S_VBUSP__RAWFE_CFG_WDRMRG1_WDRTHR_BF
0x144 IVPAC_TOP_0__CFG_SLV__PAR_VPAC_VISS0__S_VBUSP__VISS_RAWFE__CFG__MMR__S_VBUSP__RAWFE_CFG_WDRMRG2_AF — Second stage WDR merge parameter AF
  fields as IVPAC_TOP_0__CFG_SLV__PAR_VPAC_VISS0__S_VBUSP__VISS_RAWFE__CFG__MMR__S_VBUSP__RAWFE_CFG_WDRMRG1_AF
0x148 IVPAC_TOP_0__CFG_SLV__PAR_VPAC_VISS0__S_VBUSP__VISS_RAWFE__CFG__MMR__S_VBUSP__RAWFE_CFG_WDRMRG2_MA — Second stage WDR merge parameter MA
  fields as IVPAC_TOP_0__CFG_SLV__PAR_VPAC_VISS0__S_VBUSP__VISS_RAWFE__CFG__MMR__S_VBUSP__RAWFE_CFG_WDRMRG1_MA
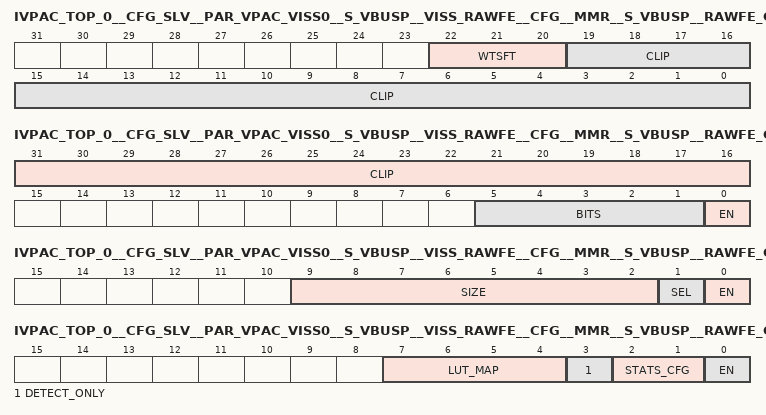
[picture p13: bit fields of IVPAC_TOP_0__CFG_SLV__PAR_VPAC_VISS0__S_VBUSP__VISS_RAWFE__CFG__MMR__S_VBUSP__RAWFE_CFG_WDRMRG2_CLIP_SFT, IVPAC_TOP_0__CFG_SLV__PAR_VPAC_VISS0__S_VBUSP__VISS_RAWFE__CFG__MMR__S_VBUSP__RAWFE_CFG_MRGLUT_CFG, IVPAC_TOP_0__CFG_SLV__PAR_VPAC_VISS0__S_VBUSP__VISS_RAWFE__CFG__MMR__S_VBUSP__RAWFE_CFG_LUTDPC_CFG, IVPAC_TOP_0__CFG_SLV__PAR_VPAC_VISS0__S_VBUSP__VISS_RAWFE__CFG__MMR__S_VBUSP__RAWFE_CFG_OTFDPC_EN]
0x14C IVPAC_TOP_0__CFG_SLV__PAR_VPAC_VISS0__S_VBUSP__VISS_RAWFE__CFG__MMR__S_VBUSP__RAWFE_CFG_WDRMRG2_CLIP_SFT — Second stage WDR merge clip value and shift before weight block
  [22:20] WTSFT — U3, shift before weight block
  [19:0] CLIP — U20, output clip value
0x150 IVPAC_TOP_0__CFG_SLV__PAR_VPAC_VISS0__S_VBUSP__VISS_RAWFE__CFG__MMR__S_VBUSP__RAWFE_CFG_MRGLUT_CFG — Merge LUT configuration
  [31:16] CLIP — U16, LUT output clip
  [5:1] BITS — U5, LUT input bit depth, up to 24
  [0] EN — LUT enable
0x154 IVPAC_TOP_0__CFG_SLV__PAR_VPAC_VISS0__S_VBUSP__VISS_RAWFE__CFG__MMR__S_VBUSP__RAWFE_CFG_LUTDPC_CFG — LUTDPC configuration
  [9:2] SIZE — U8, number of LUT entires - 1
  [1] SEL — replace with black (0) or white (1)
  [0] EN — LUTDPC enable
0x158 IVPAC_TOP_0__CFG_SLV__PAR_VPAC_VISS0__S_VBUSP__VISS_RAWFE__CFG__MMR__S_VBUSP__RAWFE_CFG_OTFDPC_EN — OTFDPC enable
  [7:4] LUT_MAP — OTF DPC THREHOLD LUT SELECTION MAPPING for 4 color channels. 0:red, 1: green, 2: blue, 3: IR. When LUT_MAP[i]=1, LUT2 threshold will be used for the color i,when LUT_MAP[i]=0, LUT1 threshold will be used for the color i.
  [3] DETECT_ONLY — OTF DPC DETECTION ONLY CFG. 0: both detection and correction, 1: only detection but not correction
  [2:1] STATS_CFG — OTF DPC STATS UPDATE CFG, 0: no update, 1: update to lower 1024 entries, 2: update to higher 1024 entries, 3: reserved
  [0] EN — OTF DPC enable. 0: disable OTF DPC (none of the other fields in OTFDPC_EN is used), 1: enable OTF DPC
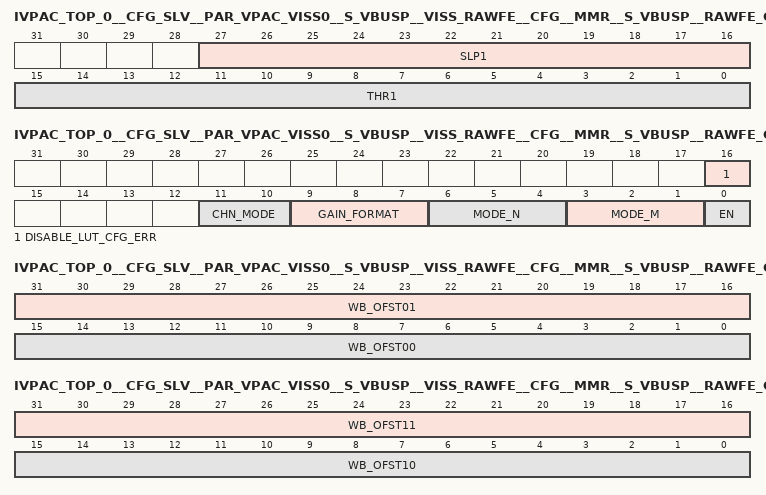
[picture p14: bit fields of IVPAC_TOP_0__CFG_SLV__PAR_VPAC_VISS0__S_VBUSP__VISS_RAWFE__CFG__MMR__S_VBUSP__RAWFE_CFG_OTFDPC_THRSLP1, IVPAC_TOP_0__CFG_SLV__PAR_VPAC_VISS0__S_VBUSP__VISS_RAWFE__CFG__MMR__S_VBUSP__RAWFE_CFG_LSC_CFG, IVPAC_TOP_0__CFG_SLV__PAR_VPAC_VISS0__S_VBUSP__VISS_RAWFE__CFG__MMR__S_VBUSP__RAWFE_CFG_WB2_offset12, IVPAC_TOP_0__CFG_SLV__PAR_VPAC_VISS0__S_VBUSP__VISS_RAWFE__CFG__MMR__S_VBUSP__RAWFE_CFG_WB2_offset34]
{0x158+4i} IVPAC_TOP_0__CFG_SLV__PAR_VPAC_VISS0__S_VBUSP__VISS_RAWFE__CFG__MMR__S_VBUSP__RAWFE_CFG_OTFDPC_THRSLP{i} (i=1..8) — OTFDPC threshold and slope {i}
  [27:16] SLP1 — S12Q8, slope at x-position {i}
  [15:0] THR1 — U16, threshold at x-position {i}
0x17C IVPAC_TOP_0__CFG_SLV__PAR_VPAC_VISS0__S_VBUSP__VISS_RAWFE__CFG__MMR__S_VBUSP__RAWFE_CFG_LSC_CFG — LSC configuration
  [16] DISABLE_LUT_CFG_ERR — Enable/disable lut_cfg_err interrupt. 0: lut_cfg_err interrupt is enabled, 1: lut_cfg_err interrupt is disabled to allow SW to reconfig currently unused upper or lower 4 channels of LUT for dual 4 channel support.
  [11:10] CHN_MODE — LSC color channel mode, 0: legacy 4 channel mode, 1: new 4 channel mode (LUT is specified for grid corner for all colors), 2: 8 channel mode, 3: reserved
  [9:7] GAIN_FORMAT — LSC LUT gain format, 0:Q8, 1:Q8+1, 2:Q7, 3:Q7+1, 4:Q6, 5:Q6+1, 6:Q5, 7:Q5+1
  [6:4] MODE_N — vertical LSC LUT downsampling, 3:8x, 4:16x, 5:32x, 6:64x, 7:128x
  [3:1] MODE_M — horizontal LSC LUT downsampling, 3:8x, 4:16x, 5:32x, 6:64x, 7:128x
  [0] EN — LSC enable
0x180 IVPAC_TOP_0__CFG_SLV__PAR_VPAC_VISS0__S_VBUSP__VISS_RAWFE__CFG__MMR__S_VBUSP__RAWFE_CFG_WB2_offset12 — WB2 white balance offset 1 and 2
  [31:16] WB_OFST01 — S16, WB offset at pixel 01
  [15:0] WB_OFST00 — S16, WB offset at pixel 00
0x184 IVPAC_TOP_0__CFG_SLV__PAR_VPAC_VISS0__S_VBUSP__VISS_RAWFE__CFG__MMR__S_VBUSP__RAWFE_CFG_WB2_offset34 — WB2 white balance offset 3 and 4
  [31:16] WB_OFST11 — S16, WB offset at pixel 11
  [15:0] WB_OFST10 — S16, WB offset at pixel 10
0x188 IVPAC_TOP_0__CFG_SLV__PAR_VPAC_VISS0__S_VBUSP__VISS_RAWFE__CFG__MMR__S_VBUSP__RAWFE_CFG_WB2_gain12 — WB2 white balance gain 1 and 2
  fields as IVPAC_TOP_0__CFG_SLV__PAR_VPAC_VISS0__S_VBUSP__VISS_RAWFE__CFG__MMR__S_VBUSP__RAWFE_CFG_PWL1_WB_gain12
0x18C IVPAC_TOP_0__CFG_SLV__PAR_VPAC_VISS0__S_VBUSP__VISS_RAWFE__CFG__MMR__S_VBUSP__RAWFE_CFG_WB2_gain34 — WB2 white balance gain 3 and 4
  fields as IVPAC_TOP_0__CFG_SLV__PAR_VPAC_VISS0__S_VBUSP__VISS_RAWFE__CFG__MMR__S_VBUSP__RAWFE_CFG_PWL1_WB_gain34
0x190 IVPAC_TOP_0__CFG_SLV__PAR_VPAC_VISS0__S_VBUSP__VISS_RAWFE__CFG__MMR__S_VBUSP__RAWFE_CFG_H3AMUX_CFG — H3A MUX configuration
  [8] PCIDSEL — H3A input PCID selection, 0: RAWFE selection, 1: PCID selection
  [5:2] SHIFT — U8, number of right shift, from 0 to 14
  [1:0] SEL — H3A input selection, 0: long frame, 1: short frame, 2: very short frame, 3: LSC output
0x194 IVPAC_TOP_0__CFG_SLV__PAR_VPAC_VISS0__S_VBUSP__VISS_RAWFE__CFG__MMR__S_VBUSP__RAWFE_CFG_H3ALUT_CFG — H3A LUT configuration
  [25:16] CLIP — U10, LUT output clip value
  [5:1] BITS — U5, LUT input bit depth, up to 24
  [0] EN — LUT enable
0x198 IVPAC_TOP_0__CFG_SLV__PAR_VPAC_VISS0__S_VBUSP__VISS_RAWFE__CFG__MMR__S_VBUSP__RAWFE_CFG_RAWFE_INT_STAT access not given — status/clear register for rawfe interrupts
  [10] DPC_STATS_READ_ERR — status/clear for DPC stats read error. This is set when reading by SW to DPC stats is started but the last valid stats entry is not read by the end of next frame. write 1 to clear event status, write of 0 has no affect (access R/W1TC)
  [9] LSC_CFG_ERR — status/clear for lsc config error. This is set when a write or read occurs in the middle of frame processing. This results in data corruption for the frame. write 1 to clear event status, write of 0 has no affect (access R/W1TC)
  [8] DPC_LINE_CFG_ERR — status/clear for dpc line config error. This is set when a write occurs in the middle of frame processing or read that would contend for memory access by HW. This results in data corruption for the frame. When a read to a dpc line memory is not contending with internal HW access, dpc line config error is not set. Write 1 to clear event status, write of 0 has no affect (access R/W1TC)
  [7] DPC_LUT_CFG_ERR — status/clear for dpc lut configuration error. This is set when a write or read occurs in the middle of frame processing. This results in data corruption for the frame. write 1 to clear event status, write of 0 has no affect (access R/W1TC)
  [6] H3A_ACCM_CFG_ERR — status/clear for h3a accum configuration error. This is set when a write or read occurs in the middle of frame processing. This results in data corruption for the frame. write 1 to clear event status, write of 0 has no affect (access R/W1TC)
  [5] H3A_LINE_CFG_ERR — status/clear for h3a line configuration error. This is set when a write or read occurs in the middle of frame processing. This results in data corruption for the frame. write 1 to clear event status, write of 0 has no affect (access R/W1TC)
  [4] H3A_LUT_CFG_ERR — status/clear for h3a lut configuration error. This is set when a write or read occurs in the middle of frame processing. This results in data corruption for the frame. write 1 to clear event status, write of 0 has no affect (access R/W1TC)
  [3] WDR_LUT_CFG_ERR — status/clear for wdr lut configuration error. This is set when a write or read occurs in the middle of frame processing. This results in data corruption for the frame. write 1 to clear event status, write of 0 has no affect (access R/W1TC)
  [2] LUT3_CFG_ERR — status/clear for lut3 configuration error. This is set when a write or read occurs in the middle of frame processing. This results in data corruption for the frame. write 1 to clear event status, write of 0 has no affect (access R/W1TC)
  [1] LUT2_CFG_ERR — status/clear for lut2 configuration error. This is set when a write or read occurs in the middle of frame processing. This results in data corruption for the frame. write 1 to clear event status, write of 0 has no affect (access R/W1TC)
  [0] LUT1_CFG_ERR — status/clear for lut1 configuration error. This is set when a write or read occurs in the middle of frame processing. This results in data corruption for the frame. write 1 to clear event status, write of 0 has no affect (access R/W1TC)
0x200 IVPAC_TOP_0__CFG_SLV__PAR_VPAC_VISS0__S_VBUSP__VISS_RAWFE__CFG__MMR__S_VBUSP__RAWFE_CFG_DBG_CTL — debug event and control register
  [14:12] DPC_LINE_SEL — select for which dpc line ram to read on debug interface
  [11] PIPE_ADV_EN_EVENT — enable for pixal pipe line advanced
  [10] DPC_OTF_CORR_EN_EVENT — enable for dpc otf corrected a pixel
  [9] LSE_INTF_STALL_EN_EVENT — enable for lse slave port stalled by rawfe
  [8] LSE_MST_STALL_EN_EVENT — enable for lse maaster port stalled on H3A out I/F
  [7] LSE_SLV_STALL_EN_EVENT — enable for lse not sending data in frame on pixel I/F
  [6] HE_EN_EVENT — enable for horizantal end
  [5] HS_EN_EVENT — enable for horizantal start
  [4] VE_EN_EVENT — enable for verticle end
  [3] VS_EN_EVENT — enable for verticle start
  [2] X_Y_EN_EVENT — enable for x,y position match event; Only generates event, no halt
  [1] X_Y_EN_HALT — enable for x,y position match halt; Halts Pipe, clear this bit to resume. Only way to resume is to clear this bit back to 0. You would need to clear the status bit after clearing this bit.
  [0] DBG_EN — Enable debug features, set to '0' to disable all events
0x204 IVPAC_TOP_0__CFG_SLV__PAR_VPAC_VISS0__S_VBUSP__VISS_RAWFE__CFG__MMR__S_VBUSP__RAWFE_CFG_DBG_HWBP — x,y event for event matching
  [28:16] Y_POS — pixel y position. Can not use 0 as a valid position.
  [12:0] X_POS — pixel x position. Can not use 0 as a valid position.
0x208 IVPAC_TOP_0__CFG_SLV__PAR_VPAC_VISS0__S_VBUSP__VISS_RAWFE__CFG__MMR__S_VBUSP__RAWFE_CFG_DBG_STAT1 access not given — status/clear register for debug events
  [11] PIPE_ADV_EVENT — status/clear for pixal pipe line advanced (access R/W1TC)
  [10] DPC_OTF_CORR_EVENT — status/clear for dpc otf corrected a pixel. write 1 to clear event status, write of 0 has no affect (access R/W1TC)
  [9] LSE_INTF_STALL_EVENT — status/clear for lse slave port stalled by rawfe. write 1 to clear event status, write of 0 has no affect (access R/W1TC)
  [8] LSE_MST_STALL_EVENT — status/clear for lse maaster port stalled. write 1 to clear event status, write of 0 has no affect (access R/W1TC)
  [7] LSE_SLV_STALL_EVENT — status/clear for lse not sending data in frame. write 1 to clear event status, write of 0 has no affect (access R/W1TC)
  [6] HE_EVENT — status/clear for horizantal end. write 1 to clear event status, write of 0 has no affect (access R/W1TC)
  [5] HS_EVENT — status/clear for horizantal start. write 1 to clear event status, write of 0 has no affect (access R/W1TC)
  [4] VE_EVENT — status/clear for verticle end. write 1 to clear event status, write of 0 has no affect (access R/W1TC)
  [3] VS_EVENT — status/clear for verticle start. write 1 to clear event status, write of 0 has no affect (access R/W1TC)
  [2] X_Y_EVENT — status/clear for x,y position match event. write 1 to clear event status, write of 0 has no affect (access R/W1TC)
  [1] X_Y_HALT — status/clear for x,y position match halt. write 1 to clear event status, write of 0 has no affect (access R/W1TC)
0x20C IVPAC_TOP_0__CFG_SLV__PAR_VPAC_VISS0__S_VBUSP__VISS_RAWFE__CFG__MMR__S_VBUSP__RAWFE_CFG_DBG_STAT2 ro — current x,y position in frame
  [28:16] Y_POS — current y position
  [12:0] X_POS — current x position
0x210 IVPAC_TOP_0__CFG_SLV__PAR_VPAC_VISS0__S_VBUSP__VISS_RAWFE__CFG__MMR__S_VBUSP__RAWFE_CFG_DBG_STAT3 ro reset 0x90000000 — internal state status
  [31:2] DPC_MIRROR_STAT — dpc mirror status
  [1:0] DPC_LINE_RAM_CTL — ram control for understanding the phase of DPC line rams circular buffer for debug reads (limited to line ram 0-3 for legacy mode use only)
0x214 IVPAC_TOP_0__CFG_SLV__PAR_VPAC_VISS0__S_VBUSP__VISS_RAWFE__CFG__MMR__S_VBUSP__RAWFE_CFG_DBG_STAT4 ro — internal state status
  [31:0] LSC_DBG_STAT — lsc state machine
0x220 IVPAC_TOP_0__CFG_SLV__PAR_VPAC_VISS0__S_VBUSP__VISS_RAWFE__CFG__MMR__S_VBUSP__RAWFE_CFG_CFA_CFG — CFA cfg register
  [4:2] PHASE — CFA color phase, specifies first red pixel position in first 4x2 pixel array in a frame
  [1:0] MODE — CFA pattern mode, 0: Legacy 2x2 RGB, 1:Enhanced 2x2 RGB, 2: 4x4 RGBIR, 3: reserved
0x224 IVPAC_TOP_0__CFG_SLV__PAR_VPAC_VISS0__S_VBUSP__VISS_RAWFE__CFG__MMR__S_VBUSP__RAWFE_CFG_OTFDPC_THRX12 reset 0x2000000 — OTFDPC threshold 1 and 2 x-position
  [31:16] THRX2 — U16, threshold 2 x-position. THRX2 > THRX1
  [15:0] THRX1 — U16, threshold 1 x-position. THRX1 should be only set to 0.
0x228 IVPAC_TOP_0__CFG_SLV__PAR_VPAC_VISS0__S_VBUSP__VISS_RAWFE__CFG__MMR__S_VBUSP__RAWFE_CFG_OTFDPC_THRX34 reset 0x8000400 — OTFDPC threshold 3 and 4 x-position
  [31:16] THRX4 — U16, threshold 4 x-position. THRX4 > THRX3
  [15:0] THRX3 — U16, threshold 3 x-position. THRX3 > THRX2
0x22C IVPAC_TOP_0__CFG_SLV__PAR_VPAC_VISS0__S_VBUSP__VISS_RAWFE__CFG__MMR__S_VBUSP__RAWFE_CFG_OTFDPC_THRX56 reset 0x20001000 — OTFDPC threshold 5 and 6 x-position
  [31:16] THRX6 — U16, threshold 6 x-position. THRX6 > THRX5
  [15:0] THRX5 — U16, threshold 5 x-position. THRX5 > THRX4
0x230 IVPAC_TOP_0__CFG_SLV__PAR_VPAC_VISS0__S_VBUSP__VISS_RAWFE__CFG__MMR__S_VBUSP__RAWFE_CFG_OTFDPC_THRX78 reset 0x80004000 — OTFDPC threshold 7 and 8 x-position
  [31:16] THRX8 — U16, threshold 8 x-position. THRX8 > THRX7
  [15:0] THRX7 — U16, threshold 7 x-position. THRX7 > THRX6
{0x230+4i} IVPAC_TOP_0__CFG_SLV__PAR_VPAC_VISS0__S_VBUSP__VISS_RAWFE__CFG__MMR__S_VBUSP__RAWFE_CFG_OTFDPC_LUT2_THRSLP{i} (i=1..8) — OTFDPC LUT2 threshold and slope {i}
  [27:16] SLP1 — S12Q8, slope
  [15:0] THR1 — U16, threshold
0x254 IVPAC_TOP_0__CFG_SLV__PAR_VPAC_VISS0__S_VBUSP__VISS_RAWFE__CFG__MMR__S_VBUSP__RAWFE_CFG_OTFDPC_LUT2_THRX12 reset 0x2000000 — OTFDPC LUT2 threshold 1 and 2 x-position
  [31:16] THRX2 — U16, threshold 2 x-position. THRX2 > ThRX1
  [15:0] THRX1 — U16, threshold 1 x-position. THRX1 should always be set to 0
0x258 IVPAC_TOP_0__CFG_SLV__PAR_VPAC_VISS0__S_VBUSP__VISS_RAWFE__CFG__MMR__S_VBUSP__RAWFE_CFG_OTFDPC_LUT2_THRX34 reset 0x8000400 — OTFDPC LUT2 threshold 3 and 4 x-position
  [31:16] THRX4 — U16, threshold 4 x-position. THRX4 > ThRX3
  [15:0] THRX3 — U16, threshold 3 x-position. THRX3 > ThRX2
0x25C IVPAC_TOP_0__CFG_SLV__PAR_VPAC_VISS0__S_VBUSP__VISS_RAWFE__CFG__MMR__S_VBUSP__RAWFE_CFG_OTFDPC_LUT2_THRX56 reset 0x20001000 — OTFDPC LUT2 threshold 5 and 6 x-position
  [31:16] THRX6 — U16, threshold 6 x-position. THRX6 > ThRX5
  [15:0] THRX5 — U16, threshold 5 x-position. THRX5 > ThRX4
0x260 IVPAC_TOP_0__CFG_SLV__PAR_VPAC_VISS0__S_VBUSP__VISS_RAWFE__CFG__MMR__S_VBUSP__RAWFE_CFG_OTFDPC_LUT2_THRX78 reset 0x80004000 — OTFDPC LUT2 threshold 7 and 8 x-position
  [31:16] THRX8 — U16, threshold 8 x-position. THRX8 > ThRX7
  [15:0] THRX7 — U16, threshold 7 x-position. THRX7 > ThRX6
0x264 IVPAC_TOP_0__CFG_SLV__PAR_VPAC_VISS0__S_VBUSP__VISS_RAWFE__CFG__MMR__S_VBUSP__RAWFE_CFG_OTFDPC_COUNT ro — OTFDPC detected defect pixel count
  [15:0] COUNT — U16, OTF detected defect pixel count. Saturated to 65535
0x268 IVPAC_TOP_0__CFG_SLV__PAR_VPAC_VISS0__S_VBUSP__VISS_RAWFE__CFG__MMR__S_VBUSP__RAWFE_CFG_LSC_LUT_MAP07 — LSC LUT MAP 0 to 7 define which LUT to use for the first 8 color channels in 4x4 pattern. Color channel 0 corresponds to the first pixel in a 4x4
  [3n+2:3n] MAP{n} (n=0..7) — U3, LSC LUT MAP for color channel {n}
0x26C IVPAC_TOP_0__CFG_SLV__PAR_VPAC_VISS0__S_VBUSP__VISS_RAWFE__CFG__MMR__S_VBUSP__RAWFE_CFG_LSC_LUT_MAP815 — LSC LUT MAP 8 to 15 define which LUT to use for the 2nd 8 color channels in 4x4 pattern. Color channel 8 corresponds to the 8th pixel in a 4x4
  [3n-22:3n-24] MAP{n} (n=8..15) — U3, LSC LUT MAP for color channel {n}
